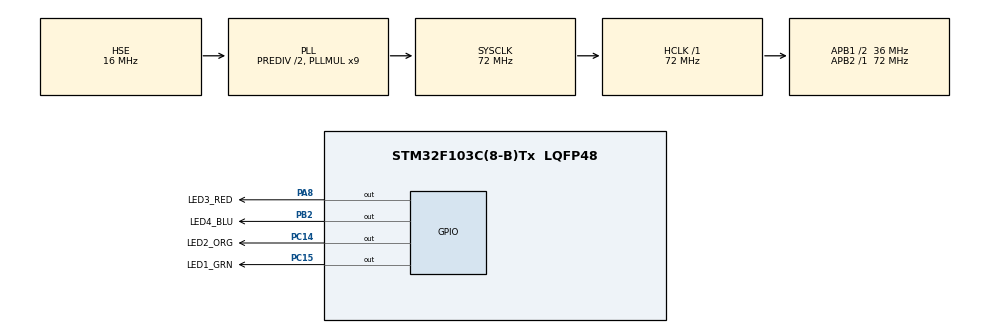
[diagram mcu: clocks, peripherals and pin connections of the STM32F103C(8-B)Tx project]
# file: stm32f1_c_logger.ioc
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Mcu.Family=STM32F1
Mcu.Name=STM32F103C(8-B)Tx
Mcu.Package=LQFP48
NVIC.PriorityGroup=NVIC_PRIORITYGROUP_4
PA13.Mode=Trace_Asynchronous_SW
PA13.Signal=SYS_JTMS-SWDIO
PA14.Mode=Trace_Asynchronous_SW
PA14.Signal=SYS_JTCK-SWCLK
PA8.GPIO_Label=LED3_RED
PA8.PinState=GPIO_PIN_SET
PA8.Signal=GPIO_Output
PB2.GPIO_Label=LED4_BLU
PB2.PinState=GPIO_PIN_SET
PB2.Signal=GPIO_Output
PB3.Mode=Trace_Asynchronous_SW
PB3.Signal=SYS_JTDO-TRACESWO
PC14-OSC32_IN.GPIO_Label=LED2_ORG
PC14-OSC32_IN.PinState=GPIO_PIN_SET
PC14-OSC32_IN.Signal=GPIO_Output
PC15-OSC32_OUT.GPIO_Label=LED1_GRN
PC15-OSC32_OUT.PinState=GPIO_PIN_SET
PC15-OSC32_OUT.Signal=GPIO_Output
PD0-OSC_IN.Mode=HSE-External-Oscillator
PD0-OSC_IN.Signal=RCC_OSC_IN
PD1-OSC_OUT.Mode=HSE-External-Oscillator
PD1-OSC_OUT.Signal=RCC_OSC_OUT
ProjectManager.HeapSize=0x200
ProjectManager.StackSize=0x400
ProjectManager.TargetToolchain=STM32CubeIDE
RCC.ADCPresc=RCC_ADCPCLK2_DIV6
RCC.AHBFreq_Value=72000000
RCC.APB1CLKDivider=RCC_HCLK_DIV2
RCC.APB1Freq_Value=36000000
RCC.APB1TimFreq_Value=72000000
RCC.APB2Freq_Value=72000000
RCC.APB2TimFreq_Value=72000000
RCC.HCLKFreq_Value=72000000
RCC.HSEDivPLL=RCC_HSE_PREDIV_DIV2
RCC.HSE_VALUE=16000000
RCC.PLLMUL=RCC_PLL_MUL9
RCC.PLLSourceVirtual=RCC_PLLSOURCE_HSE
RCC.SYSCLKFreq_VALUE=72000000
RCC.SYSCLKSource=RCC_SYSCLKSOURCE_PLLCLK
RCC.USBFreq_Value=48000000
RCC.USBPrescaler=RCC_USBCLKSOURCE_PLL_DIV1_5
board=custom

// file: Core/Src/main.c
/* USER CODE BEGIN Header */
/**
  ******************************************************************************
  * @file           : main.c
  * @brief          : Main program body
  ******************************************************************************
  * @attention
  *
  * Copyright (c) 2024 STMicroelectronics.
  * All rights reserved.
  *
  * This software is licensed under terms that can be found in the LICENSE file
  * in the root directory of this software component.
  * If no LICENSE file comes with this software, it is provided AS-IS.
  *
  ******************************************************************************
  */
/* USER CODE END Header */
#include "main.h"
#include "gpio.h"

/* USER CODE BEGIN Includes */
#include "Stm32ItmLogger.h"
/* USER CODE END Includes */

/* USER CODE BEGIN PV */

// Dynamic Debugger struct creation (use Debugger_create() constructor)
static Debugger* DBG_dynamic=NULL;
static Debugger DBG_static={.chan=0};

/* USER CODE END PV */

void SystemClock_Config(void);

int main(void)
{

  /* USER CODE BEGIN 1 */

  // Create DBG_dynamic instance
  DBG_dynamic=Debugger_create(0);

  /* USER CODE END 1 */

  /* MCU Configuration--------------------------------------------------------*/

  /* Reset of all peripherals, Initializes the Flash interface and the Systick. */
  HAL_Init();

  /* Configure the system clock */
  SystemClock_Config();

  /* Initialize all configured peripherals */
  MX_GPIO_Init();

  /* Infinite loop */
  /* USER CODE BEGIN WHILE */
  uint32_t counter = 0;
  while (1)
  {
    Debugger_log(DBG_dynamic, "counter (dynamic) = %lu (0x%04x)", counter, counter);
    Debugger_log(&DBG_static, "counter (static) = %lu (0x%04x)", counter, counter);
    counter++;
    HAL_GPIO_WritePin(LED1_GRN_GPIO_Port, LED1_GRN_Pin, counter & 2 ? GPIO_PIN_RESET : GPIO_PIN_SET);
    HAL_GPIO_WritePin(LED2_ORG_GPIO_Port, LED2_ORG_Pin, counter & 4 ? GPIO_PIN_RESET : GPIO_PIN_SET);
    HAL_GPIO_WritePin(LED3_RED_GPIO_Port, LED3_RED_Pin, counter & 8 ? GPIO_PIN_RESET : GPIO_PIN_SET);
    HAL_GPIO_WritePin(LED4_BLU_GPIO_Port, LED4_BLU_Pin, counter & 1 ? GPIO_PIN_RESET : GPIO_PIN_SET);
    /* USER CODE END WHILE */

    /* USER CODE BEGIN 3 */
    HAL_Delay(500);
  }
  /* USER CODE END 3 */
}

void SystemClock_Config(void)
{
  RCC_OscInitTypeDef RCC_OscInitStruct = {0};
  RCC_ClkInitTypeDef RCC_ClkInitStruct = {0};

  /** Initializes the RCC Oscillators according to the specified parameters
  * in the RCC_OscInitTypeDef structure.
  */
  RCC_OscInitStruct.OscillatorType = RCC_OSCILLATORTYPE_HSE;
  RCC_OscInitStruct.HSEState = RCC_HSE_ON;
  RCC_OscInitStruct.HSEPredivValue = RCC_HSE_PREDIV_DIV2;
  RCC_OscInitStruct.HSIState = RCC_HSI_ON;
  RCC_OscInitStruct.PLL.PLLState = RCC_PLL_ON;
  RCC_OscInitStruct.PLL.PLLSource = RCC_PLLSOURCE_HSE;
  RCC_OscInitStruct.PLL.PLLMUL = RCC_PLL_MUL9;
  if (HAL_RCC_OscConfig(&RCC_OscInitStruct) != HAL_OK)
  {
    Error_Handler();
  }

  /** Initializes the CPU, AHB and APB buses clocks
  */
  RCC_ClkInitStruct.ClockType = RCC_CLOCKTYPE_HCLK|RCC_CLOCKTYPE_SYSCLK
                              |RCC_CLOCKTYPE_PCLK1|RCC_CLOCKTYPE_PCLK2;
  RCC_ClkInitStruct.SYSCLKSource = RCC_SYSCLKSOURCE_PLLCLK;
  RCC_ClkInitStruct.AHBCLKDivider = RCC_SYSCLK_DIV1;
  RCC_ClkInitStruct.APB1CLKDivider = RCC_HCLK_DIV2;
  RCC_ClkInitStruct.APB2CLKDivider = RCC_HCLK_DIV1;

  if (HAL_RCC_ClockConfig(&RCC_ClkInitStruct, FLASH_LATENCY_2) != HAL_OK)
  {
    Error_Handler();
  }
}

void Error_Handler(void)
{
  __disable_irq();
  while (1)
  {
  }
}
